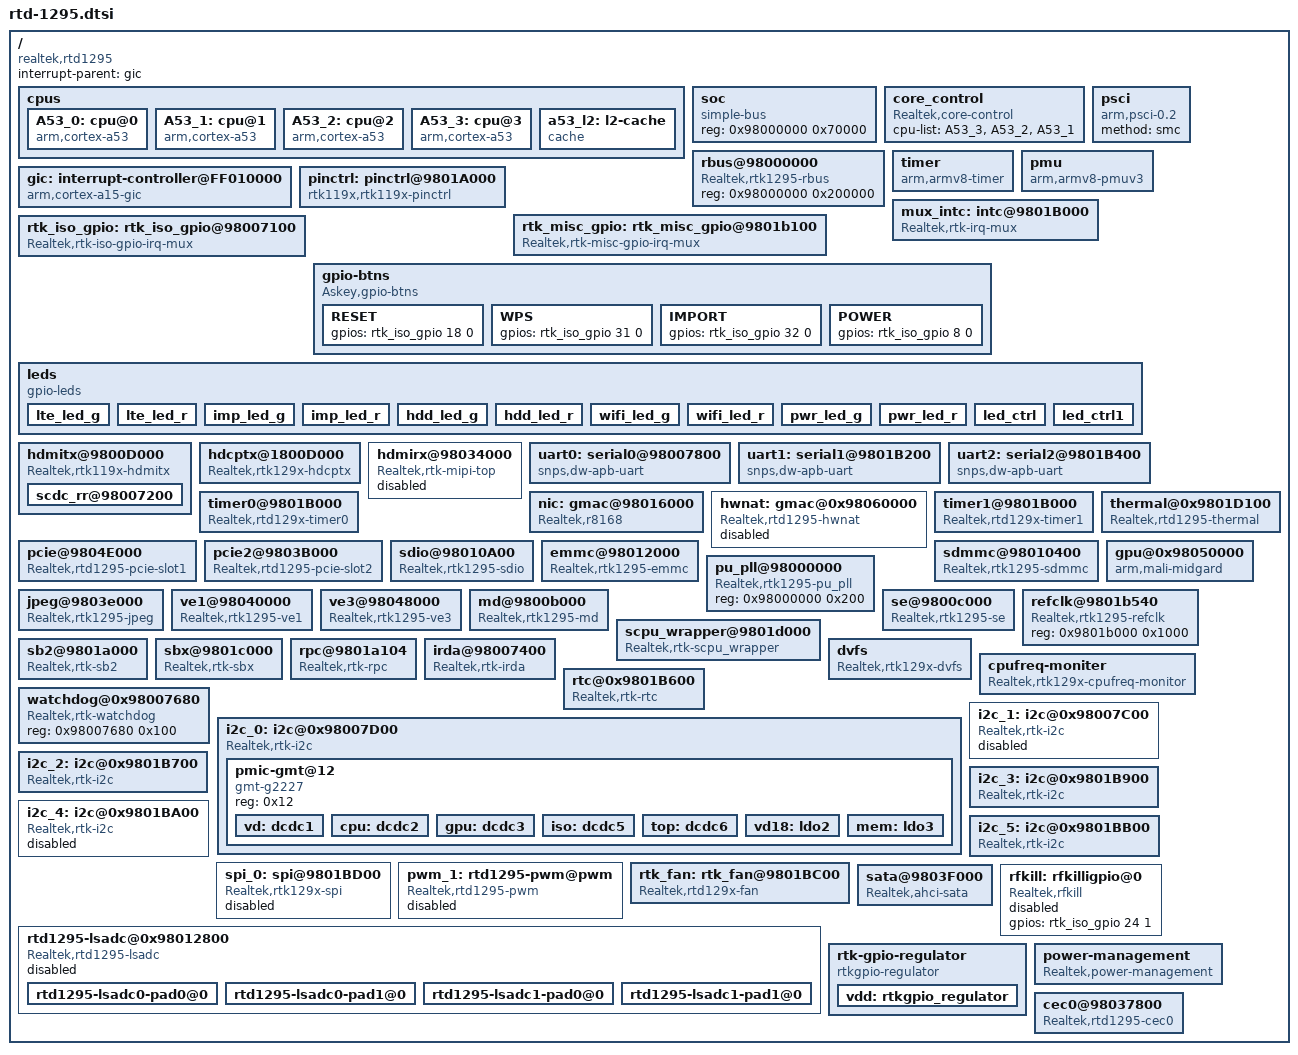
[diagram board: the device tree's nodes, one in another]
#include <dt-bindings/interrupt-controller/irq.h>
#include <dt-bindings/interrupt-controller/arm-gic.h>
/include/ "rtd-1295-pinctrl.dtsi"
/include/ "rtd-1295-irT377.dtsi"
/include/ "rtd-1295-usb.dtsi"
#include "rtd-129x-clk.dtsi"
#include "rtd-129x-reset.dtsi"
/include/ "rtd-1295-hdmirxEDID.dtsi"
/include/ "rtd-129x-powerctrl.dtsi"

/{

    compatible = "realtek,rtd1295";
    interrupt-parent = <&gic>;
    #address-cells = <1>;
    #size-cells = <1>;

    cpus {
        #address-cells = <1>;
        #size-cells = <0>;

        A53_0: cpu@0 {
            device_type = "cpu";
            compatible = "arm,cortex-a53", "arm,armv8";
            reg = <0x0>;
            /*enable-method = "psci";*/
            enable-method = "rtk-spin-table";
            cpu-release-addr = <0x0 0x9801AA44>;
            next-level-cache = <&a53_l2>;
        };

        A53_1: cpu@1 {
            device_type = "cpu";
            compatible = "arm,cortex-a53", "arm,armv8";
            reg = <0x1>;
            /*enable-method = "psci";*/
            enable-method = "rtk-spin-table";
            cpu-release-addr = <0x0 0x9801AA44>;
            next-level-cache = <&a53_l2>;
        };

        A53_2: cpu@2 {
            device_type = "cpu";
            compatible = "arm,cortex-a53", "arm,armv8";
            reg = <0x02>;
            /*enable-method = "psci";*/
            enable-method = "rtk-spin-table";
            cpu-release-addr = <0x0 0x9801AA44>;
            next-level-cache = <&a53_l2>;
        };

        A53_3: cpu@3 {
            device_type = "cpu";
            compatible = "arm,cortex-a53", "arm,armv8";
            reg = <0x03>;
            /*enable-method = "psci";*/
            enable-method = "rtk-spin-table";
            cpu-release-addr = <0x0 0x9801AA44>;
            next-level-cache = <&a53_l2>;
        };

        a53_l2: l2-cache {
            compatible = "cache";
        };
    };

    soc {
        #address-cells = <1>;
        #size-cells = <1>;
        reg = <0x98000000 0x70000>;
        compatible = "simple-bus";
        device_type = "soc";
        ranges;
    };

    core_control {
        compatible = "Realtek,core-control";
        cpu-list = <&A53_3>, <&A53_2>, <&A53_1>;
    };

    rbus@98000000 {
        compatible = "Realtek,rtk1295-rbus";
        reg = <0x98000000 0x200000>;
    };

    psci {
        compatible = "arm,psci-0.2", "arm,psci";
        method = "smc";
    };

    timer {
        compatible = "arm,armv8-timer";
        interrupts = <1 13 0xf08>,
                     <1 14 0xf08>,
                     <1 11 0xf08>,
                     <1 10 0xf08>;
        clock-frequency = <33000000>;
    };

    gic: interrupt-controller@FF010000 {
        compatible = "arm,cortex-a15-gic";
        #interrupt-cells = <3>;
        interrupt-controller;
        reg = <0xFF011000 0x1000>,
              <0xFF012000 0x1000>;
    };

    pmu {
        compatible = "arm,armv8-pmuv3";
        interrupts = <0 48 4>;
        interrupt-affinity = <&A53_0>,
                             <&A53_1>,
                             <&A53_2>,
                             <&A53_3>;
    };

    pinctrl: pinctrl@9801A000 {
        compatible = "rtk119x,rtk119x-pinctrl";
        reg = <0x9801A000 0x97c>, <0x9804d000 0x010>, <0x98012000 0x640>, <0x98007000 0x340>;
        #gpio-range-cells = <3>;

        pinctrl-names = "default";
        pinctrl-0 = <&sdcard_pins_low>,
                    <&sdcard_pins_high>,
                    <&uart0_pins>,
                    <&uart1_pins>,
                    <&uart2_pins_0>,
                    <&i2c_pins_0>,
                    //<&i2c_pins_1>,
                    <&i2c_pins_5>,
                    <&i2c_pins_6>,
                    <&pcie_clk_pins>,
                    <&rgmii0_pins>,
                    <&ir_rx_pins>,
                    <&ir_tx_pins>,
                    //<&spdif_pins>,
                    <&spi_pins_loc_gpio>, /* <&spi_pins_loc_gpio>: GPIO0~3 mux to gpio; <&spi_pins_loc_spi>: GPIO0~3 mux to SPI*/
                    //<&pwm1_pins>,
                    <&dc_fan_sensor_pins>,
                    <&etn_led_pins>;
    };

    mux_intc: intc@9801B000 {
        compatible = "Realtek,rtk-irq-mux";
        Realtek,mux-nr = <2>;
        #interrupt-cells = <2>;
        interrupt-controller;
        reg = <0x9801B000 0x100>, /* MISC_TOP MISC_ISO */
              <0x98007000 0x100>;
        interrupts = <0 40 4>, <0 41 4>;
        intr-status = <0xc>, <0x0>;
        intr-en = <0x80>, <0x40>;
    };

    rtk_misc_gpio: rtk_misc_gpio@9801b100 {
        compatible = "Realtek,rtk-misc-gpio-irq-mux";
        gpio-controller;
        #gpio-cells = <3>;                              /*must be the same with gpiochip.of_gpio_n_cells*/
        Realtek,gpio_base = <0>;
        Realtek,gpio_numbers = <101>;
        interrupt-parent = <&mux_intc>;
        #interrupt-cells = <1>;
        interrupt-controller;
        interrupts = <0 19>, <0 20>;                        /*GPIOA_INT   GPIODA_INT*/
        reg = <0x9801b000 0x100>, <0x9801b100 0x100>;       /* MISC_SYS MISC_GPIO*/
        gpio-ranges = <&pinctrl 0 0 101>;
    };

    rtk_iso_gpio: rtk_iso_gpio@98007100 {
        compatible = "Realtek,rtk-iso-gpio-irq-mux";
        gpio-controller;
        #gpio-cells = <3>;
        Realtek,gpio_base = <101>;
        Realtek,gpio_numbers = <35>;
        interrupt-parent = <&mux_intc>;
        #interrupt-cells = <1>;
        interrupt-controller;
        interrupts = <1 19>, <1 20>;                        /*GPIOA_INT   GPIODA_INT*/
        reg = <0x98007000 0x100>, <0x98007100 0x100>;       /* ISO_SYS ISO_GPIO*/
        gpio-ranges = <&pinctrl 0 101 35>;

        /* lte power on */
        gpios = <&rtk_iso_gpio 19 1 1>;
    };

    gpio-btns {
        compatible = "Askey,gpio-btns";
        RESET {
            gpios = <&rtk_iso_gpio 18 0 0>;
        };
        WPS {
            gpios = <&rtk_iso_gpio 31 0 0>;
        };
        IMPORT {
            gpios = <&rtk_iso_gpio 32 0 0>;
        };
        POWER {
            gpios = <&rtk_iso_gpio 8 0 0>;
        };
    };

    leds {
        compatible = "gpio-leds";
        lte_led_g {
		gpios = <&rtk_misc_gpio 19 1 1>;
		default-state = "on";
		status = "okay";
	};

        lte_led_r {
		gpios = <&rtk_misc_gpio 17 1 1>;
		default-state = "on";
		status = "okay";
	};

        imp_led_g {
		gpios = <&rtk_misc_gpio 5 1 1>;
		default-state = "on";
		status = "okay";
	};

        imp_led_r {
		gpios = <&rtk_misc_gpio 100 1 1>;
		default-state = "on";
		status = "okay";
	};

        hdd_led_g {
		gpios = <&rtk_misc_gpio 6 1 1>;
		default-state = "on";
		status = "okay";
	};

        hdd_led_r {
		gpios = <&rtk_misc_gpio 7 1 1>;
		default-state = "on";
		status = "okay";
	};

        wifi_led_g {
		gpios = <&rtk_misc_gpio 8 1 1>;
		default-state = "on";
		status = "okay";
	};

        wifi_led_r {
		gpios = <&rtk_iso_gpio 7 1 1>;
		default-state = "on";
		status = "okay";
	};

        pwr_led_g {
		gpios = <&rtk_iso_gpio 29 1 0>;
		default-state = "off";
		status = "okay";
                linux,default-trigger = "timer";
	};

        pwr_led_r {
		gpios = <&rtk_iso_gpio 30 1 1>;
		default-state = "on";
		status = "okay";
	};

        led_ctrl {
		gpios = <&rtk_iso_gpio 21 1 0>;
		default-state = "off";
		status = "okay";
	};

        led_ctrl1 {
		gpios = <&rtk_iso_gpio 20 1 1>;
		default-state = "on";
		status = "okay";
	};
    };

    hdmitx@9800D000 {
        compatible = "Realtek,rtk119x-hdmitx";
		reg = <0x9800d000 0x560>,<0x98007200 0x4>; /* HDMITX, I2C1_REQ_CTRL */
        gpios = <&rtk_iso_gpio 6 0 0>; /*HPD, input, default N/A */
        interrupt-parent = <&rtk_iso_gpio>;
        interrupts = <6>; /*HPD*/
        status = "okay";

		scdc_rr@98007200 {
			enable-scdc-rr = <0>;
			interrupt-parent = <&mux_intc>;
			#interrupt-cells = <1>;
			interrupt-controller;
			interrupts = <1 31>;
		};
    };

    hdcptx@1800D000 {
        compatible = "Realtek,rtk129x-hdcptx";
        reg = <0x9800d000 0x400>;
        interrupts = <0 31 4>;   /*gen Ri*/
    };

    hdmirx@98034000 {
        compatible = "Realtek,rtk-mipi-top";
        reg = <0x98037000 0xE0>,
              <0x98034000 0xF54>,
              <0x98035F00 0x2C>,
              <0x98037700 0x98>,
              <0x98004000 0xF0>,
              <0x98004100 0x104>;
        interrupts = <0 23 4>;
        gpio-rx-hpd-ctrl = <&rtk_iso_gpio 22 1 0>;
        power-saving = <0>; /* 1:ON,0:OFF; Turn off RX when cable unplugged */
        status = "disabled";
    };

    uart0: serial0@98007800 {
        compatible = "snps,dw-apb-uart";
        interrupt-parent = <&mux_intc>;
        reg = <0x98007800 0x400>,
              <0x98007000 0x100>;
        interrupts-st-mask = <0x4>;
        interrupts = <1 2>;
        reg-shift = <2>;
        reg-io-width = <4>;
        clock-frequency = <3300000>; /* This value must be override by the board. */
    };

    uart1: serial1@9801B200 {
        compatible = "snps,dw-apb-uart";
        interrupt-parent = <&mux_intc>;
        reg = <0x9801B200 0x100>,
              <0x9801B00c 0x100>;
        interrupts-st-mask = <0x8>;
        interrupts = <0 3>, <0 5>;      /*UR1_INT and UR1_TO_INT*/
        reg-shift = <2>;
        reg-io-width = <4>;
        clocks = <&clk_enable_2 28>;
        resets = <&rst2 28>;
        /* This value must be overriden by the board. */
        clock-frequency = <0>;
    };

    uart2: serial2@9801B400 {
        compatible = "snps,dw-apb-uart";
        interrupt-parent = <&mux_intc>;
        reg = <0x9801B400 0x100>,
              <0x9801B00c 0x100>;
        interrupts-st-mask = <0x100>;
        interrupts = <0 8>, <0 13>;      /*UR2_INT and UR2_TO_INT*/
        reg-shift = <2>;
        reg-io-width = <4>;
        clocks = <&clk_enable_2 27>;
        resets = <&rst2 27>;
        /* This value must be overriden by the board. */
        clock-frequency = <0>;
        status = "okay"; /* Askey Default open uart2 */
    };

    nic: gmac@98016000 {
        compatible = "Realtek,r8168";
        reg = <0x98016000 0x1000>,
              <0x98007000 0x1000>;
        interrupts = <0 22 4>;
        rtl-config = <1>;
        mac-version = <42>;    /* RTL_GIGA_MAC_VER_42 */
        rtl-features = <2>;    /* BIT(2) GMii */
        status = "okay";
    };

    hwnat: gmac@0x98060000 {
        compatible = "Realtek,rtd1295-hwnat";
        reg = <0x98060000 0x170000>,    /* NAT */
              <0x98000000 0x20000>,    /* CLK SYS */
              <0x9803FF00 0x100>;    /* SATA Wrapper */
        interrupts = <0 24 4>;
        offload_enable = <0>; /* 0:disable, 1:enable HW NAT offload */
        rgmii_voltage = <1>; /* 1:1.8V, 2: 2.5V, 3:3.3V */
        mac0_enable = <0>; /* 0:disable, 1:enable */
        mac0_mode = <1>; /* 0:RGMII, 1:SGMII */
        mac5_conn_to = <0>; /* 0:PHY, 1:MAC */
        mac0_phy_id = <3>; /* PHY ID 2 for RGMII, 3 for SGMII */
        mac4_phy_id = <4>;
        mac5_phy_id = <1>;
        status = "disabled";
    };

    timer0@9801B000 {
        compatible = "Realtek,rtd129x-timer0";
        reg = <0x9801B000 0x600>,
              <0xFF018000 0x10>;
        interrupts = <0 17 4>;
        clock-frequency = <3300000>;
        status = "okay";
    };

    timer1@9801B000 {
        compatible = "Realtek,rtd129x-timer1";
        reg = <0x9801B000 0x600>,
              <0xFF018000 0x10>;
        interrupts = <0 18 4>;
        clock-frequency = <3300000>;
        status = "okay";
    };

    thermal@0x9801D100 {
        compatible = "Realtek,rtd1295-thermal";
        reg = <0x9801D100 0x70>;
        thermal0-disable = <0>;
        thermal1-disable = <0>;
        thermal-polling-ms = <500>;
        thermal-trend-urgent = <0>;
        /* trip points -----------------------  */
        /*         | temp | hyst |   cdev    |  */
        /*         |      |      | id | data |  */
        trip-points = <
            /* 0 */   105      3    0      0
            /* 1 */   110      3    0      1
            /* 2 */   115      3    0      2
            /* 3 */   110      7    1      0
            /* 4 */   130      0    3      0
        >;
        /* freq range (KHz) to each trip point */
        cpufreq,freqs = <
            1400000  1300000 /* bind to trip-point 0 */
            1200000  1100000 /* bind to trip-point 1 */
            1000000   300000 /* bind to trip-point 2 */
        >;
        /* cpu core list used by the cooling device */
        cpu-core,cpu-list = <&A53_3>, <&A53_2>;

        status = "okay";
    };

    pcie@9804E000 {
        compatible = "Realtek,rtd1295-pcie-slot1";
        reg = <0x9804E000 0x00001000
               0x9804F000 0x00001000
               0x9801C600 0x00000100
               0x9801A000 0x00000300
               0x98012000 0x00001000>;
        interrupt-names = "rtk-pcie1-intr";
        #interrupt-cells = <1>;
        interrupt-map-mask = <0 0 0 0>;
        interrupt-map = <0 0 0 0 &gic GIC_SPI 61 IRQ_TYPE_LEVEL_HIGH>;
        bus-range = <0x00 0xff>;
        linux,pci-domain = <0>;
        device_type = "pci";
        gpios = <&rtk_misc_gpio 18 1 1>;
        #size-cells = <2>;
        #address-cells = <3>;
        num-lanes = <1>;
        ranges = <0x02000000 0x00000000 0xC0000000  0xC0000000 0x00000000 0x01000000
                  0x01000000 0x00000000 0x00030000  0x00030000 0x00000000 0x00010000>;
        status = "okay";
    };

    pcie2@9803B000 {
        compatible = "Realtek,rtd1295-pcie-slot2";
        reg = <0x9803B000 0x00001000
               0x9803C000 0x00001000
               0x9801C600 0x00000100
               0x9801A000 0x00000300
               0x98012000 0x00001000>;
        interrupt-names = "rtk-pcie2-intr";
        #interrupt-cells = <1>;
        interrupt-map-mask = <0 0 0 0>;
        interrupt-map = <0 0 0 0 &gic GIC_SPI 62 IRQ_TYPE_LEVEL_HIGH>;
        bus-range = <0x00 0xff>;
        linux,pci-domain = <1>;
        device_type = "pci";
        gpios = <&rtk_misc_gpio 20 1 1>;
        #size-cells = <2>;
        #address-cells = <3>;
        num-lanes = <1>;
        ranges = <0x02000000 0x00000000 0xC1000000  0xC1000000 0x00000000 0x01000000
                  0x01000000 0x00000000 0x00040000  0x00040000 0x00000000 0x00010000>;
        speed-mode = <0>; // 0:GEN1, 1:GEN2
        status = "okay";
    };

    sdio@98010A00 {
        compatible = "Realtek,rtk1295-sdio";
        gpios = <&rtk_iso_gpio 23 1 1>;
        reg = <0x98010c00 0x200>,
              <0x98000000 0x200000>;
        interrupts = <0 45 4>;
    };

    sdmmc@98010400 {
        compatible = "Realtek,rtk1295-sdmmc";
        gpios = <&rtk_misc_gpio 99 1 0>;    /*sd power , output, default high  (poweroff) */
        reg = <0x98000000 0x400>, /* CRT */
              <0x98010400 0x200>, /* SDMMC */
              <0x9801A000 0x400>, /* BS2 */
              <0x98012000 0xa00>, /* EMMC */
              <0x98010A00 0x40>; /* SDIO */
        interrupts = <0 44 4>;
        status = "okay";
    };

    emmc@98012000 {
        compatible = "Realtek,rtk1295-emmc";
        reg = <0x98012000 0xa00>, /*EMMC*/
              <0x98000000 0x600>, /*CRT */
              <0x9801A000 0x80>,  /*SB2*/
              <0x9801B000 0x150>;  /*MISC*/
        interrupts = <0 42 4>;
        speed-step = <2>; /* 0: sdr50, 1: ddr50, 2: hs200, 3: hs400 */
		pddrive_nf_s0 = <1 0x77 0x77 0x77 0x33>;    /* pddrive_nf0, pddrive_nf1, pddrive_nf2, pddrive_nf3, pddrive_nf4 ; for sdr50 */
                pddrive_nf_s2 = <1 0xbb 0xbb 0xbb 0x33>;    /* pddrive_nf0, pddrive_nf1, pddrive_nf2, pddrive_nf3, pddrive_nf4 ; for hs200 */
                phase_tuning = <0 0>; /* arg0: tx tuning switch, arg1: rx tuning switch*/
    };

    gpu@0x98050000 {
        compatible = "arm,mali-midgard";
        reg = <0x98050000 0xffff>;
        interrupts = <0 67 4>, <0 68 4>, <0 66 4>;
        interrupt-names = "JOB", "MMU", "GPU";
        clocks = <&clk_gpu>;
        clocks-names = "clk_gpu";
        operating-points = <
        /* KHz uV */
        520000 1000000
        300000 900000
        >;
    };

    pu_pll@98000000 {
        compatible = "Realtek,rtk1295-pu_pll";
        reg = <0x98000000 0x200>;
    };

    jpeg@9803e000 {
        compatible = "Realtek,rtk1295-jpeg";
        reg = <0x9803e000 0x1000>, <0x98000000 0x200>;
        interrupts = <0 52 4>;
    };

    ve1@98040000 {
        compatible = "Realtek,rtk1295-ve1";
        reg = <0x98040000 0x8000>, <0x98000000 0x200>;
        interrupts = <0 53 4>, <0 54 4>;
	clocks = <&clk_ve1>, <&clk_ve2>, <&clk_sysh>;
	clock-names = "clk_ve1","clk_ve2", "clk_sysh";
	resets = <&rst1 13>, <&rst1 14>;
	reset-names = "ve1", "ve2";
    };

    ve3@98048000 {
        compatible = "Realtek,rtk1295-ve3";
        reg = <0x98048000 0x4000>, <0x98000000 0x200>;
        interrupts = <0 55 4>;
	clocks = <&clk_ve3>;
	resets = <&rst1 15>;
    };

    md@9800b000 {
        compatible = "Realtek,rtk1295-md";
        reg = <0x9800b000 0x1000>;
        interrupts = <0 38 4>;  /* 70 - 32 = 38 */
    };

    se@9800c000 {
        compatible = "Realtek,rtk1295-se";
        reg = <0x9800c000 0x1000>;
        interrupts = <0 20 4>;  /* 52 - 32 = 20 */
    };

    refclk@9801b540 {
        compatible = "Realtek,rtk1295-refclk";
        reg = <0x9801b000 0x1000>;
    };

    scpu_wrapper@9801d000 {
        compatible = "Realtek,rtk-scpu_wrapper";
        reg = <0x9801d000 0x500>;
        interrupts = <0 46 4>;
    };

    sb2@9801a000 {
        compatible = "Realtek,rtk-sb2";
        reg = <0x9801a000 0x900>;
        interrupts = <0 36 4>;
    };

    sbx@9801c000 {
	compatible = "Realtek,rtk-sbx";
        reg = <0x9801c000 0x18>,   /* sb1 */
              <0x9801c200 0x18>,   /* sb3 */
              <0x9801c400 0x10>,   /* sb0 */
              <0x9801c600 0x18>;   /* sb4 */

    };

    rpc@9801a104 {
        compatible = "Realtek,rtk-rpc";
        reg = <0x9801a104 0xc>,    /* rpc intr en */
              <0x01ffe000 0x4000>, /* rpc ring buffer */
              <0x0001f000 0x1000>, /* rpc common */
              <0x9801a020 0x4>;    /* rbus sync */
        interrupts = <0 33 4>;
    };

    irda@98007400 {
        compatible = "Realtek,rtk-irda";
        interrupt-parent = <&mux_intc>;
        reg = <0x98007000 0x400>, <0x98007400 0x100>;
        interrupts = <1 5>;
        status = "okay";
    };

    dvfs: dvfs {
        compatible = "Realtek,rtk129x-dvfs";
        transition_latency = <500000>; // nanoseconds
        rm-threshold-uV = <950000>;
        voltage-step-ctl = <0>;
        gpios = <&rtk_iso_gpio 15 1 1>, <&rtk_iso_gpio 16 1 1>;
        status = "okay";
    };

    cpufreq-moniter {
        compatible = "Realtek,rtk129x-cpufreq-monitor";
        clocks = <&clk_gpu>, <&clk_ve1>, <&clk_ve2>, <&clk_ve3>;
        clock-names = "clk_gpu", "clk_ve1", "clk_ve2", "clk_ve3";
        enable-ve-monitor;
        enable-gpu-monitor;
        enable-io-monitor;
        status = "okay";
    };

    rtc@0x9801B600 {
        compatible = "Realtek,rtk-rtc";
        reg = <0x9801B600 0x100>,
              <0x98000000 0x100>,
              <0x98007000 0x100>;
	rtc-base-year = <2016>;
    	status = "okay";
    };

    watchdog@0x98007680 {
        compatible = "Realtek,rtk-watchdog";
        reg = <0x98007680 0x100>;
    };

    i2c_0: i2c@0x98007D00 {
        compatible = "Realtek,rtk-i2c";
        reg = <0x98007D00 0x400>;
        interrupt-parent = <&mux_intc>;
        interrupts = <1 8>;
        i2c-num = <0>;
        status = "okay";
        #address-cells = <1>;
        #size-cells = <0>;
        pmic-gmt@12 {
            compatible = "gmt-g2227";
            reg = <0x12>;
            vd: dcdc1 {
                regulator-min-microvolt = <3000000>;
                regulator-max-microvolt = <3300000>;
            };
            cpu: dcdc2 {
                regulator-min-microvolt = <800000>;
                regulator-max-microvolt = <1187500>;
                sleep-volt = <0>;
            };
            gpu: dcdc3 {
                regulator-min-microvolt = <800000>;
                regulator-max-microvolt = <1187500>;
                sleep-volt = <0>;
            };
            iso: dcdc5 {
                regulator-min-microvolt = <800000>;
                regulator-max-microvolt = <1187500>;
            };
            top: dcdc6 {
                regulator-min-microvolt = <800000>;
                regulator-max-microvolt = <1187500>;
                sleep-volt = <0>;
            };
            vd18: ldo2 {
                regulator-min-microvolt = <1500000>;
                regulator-max-microvolt = <1900000>;
                sleep-volt = <0>;
            };
            mem: ldo3 {
                regulator-min-microvolt = <800000>;
                regulator-max-microvolt = <1200000>;
                sleep-volt = <0>;
            };
        };
    };

    i2c_1: i2c@0x98007C00 {
        compatible = "Realtek,rtk-i2c";
        reg = <0x98007C00 0x400>;
        interrupt-parent = <&mux_intc>;
        interrupts = <1 11>;
        i2c-num = <1>;
        status = "disabled";
        #address-cells = <1>;
        #size-cells = <0>;
    };

    i2c_2: i2c@0x9801B700 {
        compatible = "Realtek,rtk-i2c";
        reg = <0x9801B700 0x400>;
        interrupt-parent = <&mux_intc>;
        interrupts = <0 26>;
        i2c-num = <2>;
        status = "okay";
        #address-cells = <1>;
        #size-cells = <0>;
    };

    i2c_3: i2c@0x9801B900 {
        compatible = "Realtek,rtk-i2c";
        reg = <0x9801B900 0x400>;
        interrupt-parent = <&mux_intc>;
        interrupts = <0 23>;
        i2c-num = <3>;
        status = "okay";
        #address-cells = <1>;
        #size-cells = <0>;
    };

    i2c_4: i2c@0x9801BA00 {
        compatible = "Realtek,rtk-i2c";
        reg = <0x9801BA00 0x400>;
        interrupt-parent = <&mux_intc>;
        interrupts = <0 15>;
        i2c-num = <4>;
        status = "disabled";
        #address-cells = <1>;
        #size-cells = <0>;
    };

    i2c_5: i2c@0x9801BB00 {
        compatible = "Realtek,rtk-i2c";
        reg = <0x9801BB00 0x400>;
        interrupt-parent = <&mux_intc>;
        interrupts = <0 14>;
        i2c-num = <5>;
        status = "okay";
        #address-cells = <1>;
        #size-cells = <0>;
    };

    spi_0: spi@9801BD00 {
        compatible = "Realtek,rtk129x-spi";
        reg = <0x9801BD00 50>;
        pinctrl-names = "default";
        pinctrl-0 = <&gspi_pins>;
        spi-cs-gpio = <&rtk_misc_gpio 6 1 1>;
        status = "disabled";
    };

    pwm_1: rtd1295-pwm@pwm {
        compatible = "Realtek,rtd1295-pwm";
        #pwm-cells = <2>;
        reg = <0x980070D0 0xC>;
        pwm_idx = <1>;
        enable = <1>;
        clkout_div = <0xff>; //default OCD: from 0x0 to 0xff
        clksrc_div = <0x1>;  //default OSD: from 0x0 to 0xf
        duty_rate = <50>;  //default duty_rate 0 ~ 100
        status = "disabled";
    };

    rtk_fan: rtk_fan@9801BC00 {
        compatible = "Realtek,rtd129x-fan";
        reg = <0x9801BC00 0x14>, <0x9801A910 0x4>;
        interrupt-parent = <&mux_intc>;
        interrupts = <0 29>;
        status = "okay";

        //pwms = <&pwm_1 1 37878>; // (1) pwm node (2) pwm id (3) out period_ns (1/26400 ns)

        timer_target = <0x100000>;
        fan_debounce = <0x0>;// 0x0~0x7
    };

    rtd1295-lsadc@0x98012800 {
        compatible = "Realtek,rtd1295-lsadc";
        interrupt-parent = <&mux_intc>;
        interrupts = <0 21>, <0 22>;    /* LSADC0_INT, LSADC1_INT */
        reg = <0x9801B000 0x100>,     /* MISC_TOP MISC_ISO */
              <0x98012800 0x200>;     /* LSADC */
        status = "disabled";
        clk_gating_en = <1>, /* LSADC0 0:disable; 1:enable */
                        <1>; /* LSADC1 0:disable; 1:enable */
        vdd_mux_sel = <0>; /* 0:VDD1; 1:VDD2 */
        vdd_mux1 = <0>; /* 0 ~ 15: VDD_IN source selection */
        vdd_mux2 = <0>; /* 0 ~ 15: VDD_IN source selection */
        vdd_mux_en = <1>; /* 0:disable; 1:enable */

        rtd1295-lsadc0-pad0@0 {
            //compatible = "Realtek,rtd1295-lsadc0-pad0";
            activate = <1>;    /* 0:in-activate; 1:activate */
            ctrl_mode = <0>;    /* 0:Voltage mode; 1:Current mode*/
            sw_idx = <0>;    /* 0:External input pin 0; 1:External input pin 1 */
            voltage_threshold = <32>;    /* 8 bit : 0 ~ 255 */
        };
        rtd1295-lsadc0-pad1@0 {
            //compatible = "Realtek,rtd1295-lsadc0-pad1";
            activate = <1>; /* 0:in-activate; 1:activate */
            ctrl_mode = <0>; /* 0:Voltage mode; 1:Current mode*/
            sw_idx = <1>; /* 0:External input pin 0; 1:External input pin 1 */
            voltage_threshold = <16>; /* 8 bit : 0 ~ 255 */
        };
        rtd1295-lsadc1-pad0@0 {
            //compatible = "Realtek,rtd1295-lsadc1-pad0";
            activate = <1>; /* 0:in-activate; 1:activate */
            ctrl_mode = <0>; /* 0:Voltage mode; 1:Current mode*/
            sw_idx = <0>; /* 0:VDD; 1:GND */
            voltage_threshold = <32>; /* 8 bit : 0 ~ 255 */
            detect_range_ctrl = <0>; /* 0:0V ~ 1.024V; 1:0.5V ~ 1.524V */
        };
        rtd1295-lsadc1-pad1@0 {
            //compatible = "Realtek,rtd1295-lsadc1-pad1";
            activate = <1>;    /* 0: in-activate; 1:activate */
            ctrl_mode = <0>;    /* 0: Voltage mode; 1:Current mode*/
            sw_idx = <0>;    /* 0:VDD; 1:GND */
            voltage_threshold = <16>;    /* 8 bit : 0 ~ 255 */
            detect_range_ctrl = <1>;    /* 0:0V ~ 1.024V; 1:0.5V ~ 1.524V */
        };
    };

    sata@9803F000 {
        compatible = "Realtek,ahci-sata";
        reg = <0x9803F000 0x1000>, <0x9801a900 0x100>;
        interrupts = <0 28 4>;
        gpios = <&rtk_misc_gpio 16 1 1>;
        tx-driving = <6>; /* here choose 2 ~ 6 */
        clocks = <&clk_enable_1 2>, <&clk_enable_1 7>;
        hotplug-en = <0>;
        status = "okay";
    };

    rfkill: rfkilligpio@0{
        compatible = "Realtek,rfkill";
        gpios = <&rtk_iso_gpio 24 1 0>;    /*bt power , output, default low */
        status = "disabled";
    };

    rtk-gpio-regulator {
        compatible = "rtkgpio-regulator";
        gpios = <&rtk_iso_gpio 16 1 0>, <&rtk_iso_gpio 17 1 1>;
        //status = "disabled";
        status = "okay";
        vdd: rtkgpio_regulator {
            regulator-min-microvolt = <850000>;
            regulator-max-microvolt = <1050000>;
        };
    };

    power-management{
        compatible = "Realtek,power-management";
        reg = <0x98000000 0x1800>, /* CRT */
              <0x98006000 0x1000>, /* AIO */
              <0x98007000 0x1000>, /* ISO */
              <0x98018000 0x2000>, /* TVE */
              <0x9801A000 0x1000>, /* SB2 */
              <0x9801B000 0x1000>; /* MISC */
        suspend-mode = <0>; // 0:SUSPEND_TO_RAM, 1:SUSPEND_TO_COOLBOOT, 2:SUSPEND_TO_WFI
        status = "okay";
    };
	cec0@98037800 {
		compatible = "Realtek,rtd1295-cec0";
		reg = <0x98037800 0xe0>,<0x98007000 0x100>,<0x98037500 0x100>;
		interrupts = <0 26 4>;
		module-enable = <1>;
		status = "okay";
	};
};
